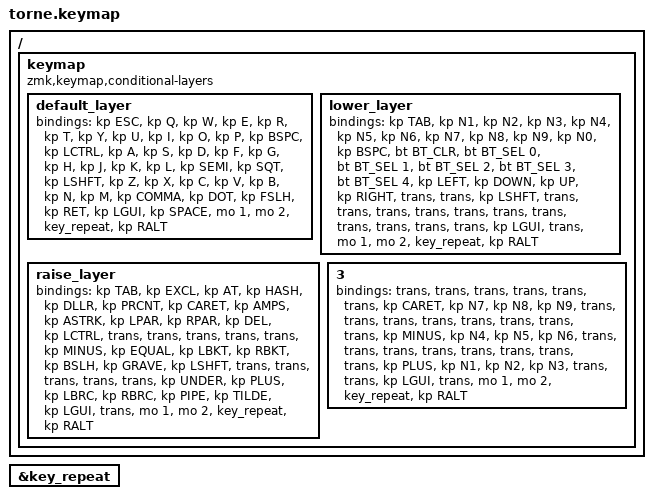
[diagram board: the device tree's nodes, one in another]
#include <behaviors.dtsi>
#include <dt-bindings/zmk/keys.h>
#include <dt-bindings/zmk/bt.h>

&key_repeat {
};

/ {
        keymap {
                compatible = "zmk,keymap,conditional-layers";

                default_layer {
// -----------------------------------------------------------------------------------------
// |  ESC |  Q  |  W  |  E  |  R  |  T  |   |  Y  |  U   |  I  |  O  |  P  | BSPC |
// | CTRL |  A  |  S  |  D  |  F  |  G  |   |  H  |  J   |  K  |  L  |  ;  |  '   |
// | SHFT |  Z  |  X  |  C  |  V  |  B  |   |  N  |  M   |  ,  |  .  |  /  | RET  |
//                    | GUI | SPC | LWR |   | ENT | RSE  | ALT |
                        bindings = <
   &kp ESC   &kp Q &kp W &kp E &kp R &kp T   &kp Y &kp U  &kp I     &kp O   &kp P    &kp BSPC
   &kp LCTRL &kp A &kp S &kp D &kp F &kp G   &kp H &kp J  &kp K     &kp L   &kp SEMI &kp SQT
   &kp LSHFT &kp Z &kp X &kp C &kp V &kp B   &kp N &kp M  &kp COMMA &kp DOT &kp FSLH &kp RET
                  &kp LGUI &kp SPACE &mo 1   &mo 2 &key_repeat &kp RALT
                        >;
                };
                
                lower_layer {
// -----------------------------------------------------------------------------------------
// |  TAB |  1  |  2  |  3  |  4  |  5  |   |  6  |  7  |  8  |  9  |  0  | BSPC |
// | BTCLR| BT1 | BT2 | BT3 | BT4 | BT5 |   | LFT | DWN |  UP | RGT |     |      |
// | SHFT |     |     |     |     |     |   |     |     |     |     |     |      |
//                    | GUI |     | SPC |   | ENT |     | ALT |
                        bindings = <
   &kp TAB    &kp N1       &kp N2       &kp N3       &kp N4       &kp N5         &kp N6   &kp N7   &kp N8 &kp N9    &kp N0 &kp BSPC
   &bt BT_CLR &bt BT_SEL 0 &bt BT_SEL 1 &bt BT_SEL 2 &bt BT_SEL 3 &bt BT_SEL 4   &kp LEFT &kp DOWN &kp UP &kp RIGHT &trans &trans
   &kp LSHFT  &trans       &trans       &trans       &trans       &trans         &trans   &trans   &trans &trans    &trans &trans
                                    &kp LGUI     &trans       &mo 1      &mo 2  &key_repeat   &kp RALT
                        >;
                };

                raise_layer {
// -----------------------------------------------------------------------------------------
// |  TAB |  !  |  @  |  #  |  $  |  %  |   |  ^  |  &  |  *  |  (  |  )  | DEL |
// | CTRL |     |     |     |     |     |   |  -  |  =  |  [  |  ]  |  \  |  `   |
// | SHFT |     |     |     |     |     |   |  _  |  +  |  {  |  }  | "|" |  ~   |
//                    | GUI |     | SPC |   | ENT |     | ALT |
                        bindings = <
   &kp  TAB  &kp EXCL &kp AT &kp HASH &kp DLLR &kp PRCNT   &kp CARET &kp AMPS  &kp ASTRK &kp LPAR &kp RPAR &kp DEL
   &kp LCTRL &trans   &trans &trans   &trans   &trans      &kp MINUS &kp EQUAL &kp LBKT  &kp RBKT &kp BSLH &kp GRAVE
   &kp LSHFT &trans   &trans &trans   &trans   &trans      &kp UNDER &kp PLUS  &kp LBRC  &kp RBRC &kp PIPE &kp TILDE
                             &kp LGUI &trans   &mo 1   &mo 2   &key_repeat    &kp RALT
                        >;
                };

                3 {
// -----------------------------------------------------------------------------------------
// |  TAB |  !  |  @  |  #  |  $  |  %  |   |  ^  |  &  |  *  |  (  |  )  | DEL |
// | CTRL |     |     |     |     |     |   |  -  |  =  |  [  |  ]  |  \  |  `   |
// | SHFT |     |     |     |     |     |   |  _  |  +  |  {  |  }  | "|" |  ~   |
//                    | GUI |     | SPC |   | ENT |     | ALT |
                        bindings = <
   &trans &trans &trans &trans &trans &trans      &kp CARET &kp N7 &kp N8 &kp N9 &trans &trans
   &trans &trans &trans &trans &trans &trans      &kp MINUS &kp N4 &kp N5 &kp N6 &trans &trans
   &trans &trans &trans &trans &trans &trans      &kp PLUS  &kp N1 &kp N2 &kp N3 &trans &trans
                     &kp LGUI &trans   &mo 1      &mo 2  &key_repeat &kp RALT
                        >;
                };


        };
};
